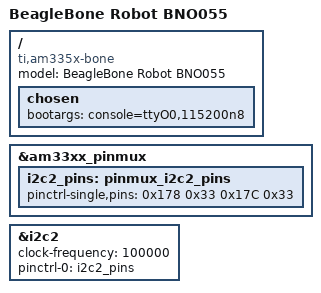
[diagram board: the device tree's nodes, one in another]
/dts-v1/;

#include "am335x-bone-common.dtsi"
#include <dt-bindings/gpio/gpio.h>
#include <dt-bindings/interrupt-controller/irq.h>

/ {
    model = "BeagleBone Robot BNO055";
    compatible = "ti,am335x-bone", "ti,am33xx";

    chosen {
        bootargs = "console=ttyO0,115200n8";
    };
};

/* =========================
 * PINMUX I2C2 (P9_19, P9_20)
 * ========================= */
&am33xx_pinmux {
    i2c2_pins: pinmux_i2c2_pins {
        pinctrl-single,pins = <
            0x178 0x33  /* P9_19 = I2C2_SCL */
            0x17C 0x33  /* P9_20 = I2C2_SDA */
        >;
    };
};

/* =========================
 * ENABLE I2C2
 * ========================= */
&i2c2 {
    status = "okay";
    clock-frequency = <100000>;

    pinctrl-names = "default";
    pinctrl-0 = <&i2c2_pins>;
};

/* =========================
 * INCLUDE SENSOR
 * ========================= */
#include "i2c-sensor.dtsi"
